# MCSPI_MCSPI_20100000h register map
Vendor: Texas Instruments
Peripheral module from a debugger description file (folder AM275x).
Registers are 32-bit, read-only, reset values left out (the file's numbers can be read two ways) unless marked. A register's access mark holds for its fields unless they carry their own. Offsets are as the file gives them; lines under a group give offsets from that group; [hi:lo] are bit positions; {n}, {i} and the like mark numbered series; 'fields as' and 'values as' point back to an identical list; <NAME> marks a mode.

## mcspi
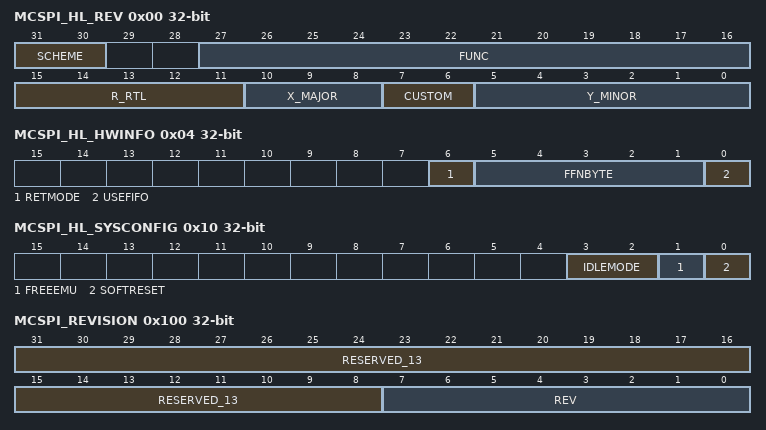
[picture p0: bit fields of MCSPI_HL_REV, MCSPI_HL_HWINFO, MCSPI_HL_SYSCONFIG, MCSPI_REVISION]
0x00 MCSPI_HL_REV — IP Revision Identifier (X.Y.R)Used by software to track features, bugs, and compatibility
  [31:30] SCHEME — Used to distinguish between old scheme and current
  [27:16] FUNC — Function indicates a software compatible module family If there is no level of software compatibility a new Func number [and hence REVISION] should be assigned
  [15:11] R_RTL — RTL Version [R], maintained by IP design owner RTL follows a numbering such as XYRZ which are explained in this table R changes ONLY when: [1] PDS uploads occur which may have been due to spec changes [2] Bug fixes occur [3] Resets to '0' when X or Y changes Design team has an internal 'Z' [customer invisible] number which increments on every drop that happens due to DV and RTL updates Z resets to 0 when R increments
  [10:8] X_MAJOR — Major Revision [X], maintained by IP specification owner X changes ONLY when: [1] There is a major feature addition An example would be adding Controller Mode to Utopia Level2 The Func field [or Class/Type in old PID format] will remain the same X does NOT change due to: [1] Bug fixes [2] Change in feature parameters
  [7:6] CUSTOM — Indicates a special version for a particular device Consequence of use may avoid use of standard Chip Support Library [CSL] / Drivers
  [5:0] Y_MINOR — Minor Revision [Y], maintained by IP specification owner Y changes ONLY when: [1] Features are scaled [up or down] Flexibility exists in that this feature scalability may either be represented in the Y change or a specific register in the IP that indicates which features are exactly available [2] When feature creeps from Is-Not list to Is list But this may not be the case once it sees silicon; in which case X will change Y does NOT change due to: [1] Bug fixes [2] Typos or clarifications [3] major functional/feature change/addition/deletion Instead these changes may be reflected via R, S, X as applicable Spec owner maintains a customer-invisible number 'S' which changes due to: [1] Typos/clarifications [2] Bug documentation Note that this bug is not due to a spec change but due to implementation Nevertheless, the spec tracks the IP bugs An RTL release [say for silicon PG11] that occurs due to bug fix should document the corresponding spec number [XYS] in its release notes
0x04 MCSPI_HL_HWINFO — Information about the IP module's hardware configuration, i.e. typically the module's HDL generics (if any).Actual field format and encoding is up to the module's designer to decide.
  [6] RETMODE — This bit field indicates whether the retention mode is supported using the pin PIRFFRET 0 Retention mode disabled1 Retention mode enabled
  [5:1] FFNBYTE — FIFO number of byte generic parameter This register defines the value of FFNBYTE generic parameter, only MSB bits from 8 down to 4 are taken into account 1 FIFO 16 bytes depth2 FIFO 32 bytes depth4 FIFO 64 bytes depth8 FIFO 128 bytes depth10 FIFO 256 bytes depth
  [0] USEFIFO — Use of a FIFO enable: This bit field indicates if a FIFO is integrated within controller design with its management 0 FIFO not implemented in design1 FIFO and its management implemented in design with depth defined by FFNBYTE generic
0x10 MCSPI_HL_SYSCONFIG rw — Clock management configuration
  [3:2] IDLEMODE — Configuration of the local target state management mode By definition, target can handle read/write transaction as long as it is out of IDLE state 0 Force-idle mode: local target's IDLE state follows (acknowledges) the system's clock stop requests unconditionally, that is, regardless of the IP module's internal requirements. Backup mode, for debug only.1 No-idle mode: local target never enters IDLE state. Backup mode, for debug only.2 Smart-idle mode: local target's IDLE state eventually follows (acknowledges) the system's clock stop requests, depending on the IP module's internal requirements. IP module shall not generate (IRQ- or DMA- request-related) wake-up events.3 Smart-idle wake-up-capable mode: local target's IDLE state eventually follows (acknowledges) the system's clock stop requests, depending on the IP module's internal requirements. IP module may generate (IRQ- or DMA-request-related) wake-up events when in IDLE state.
  [1] FREEEMU — Sensitivity to emulation [debug] suspend input signal 0 IP module is sensitive to emulation suspend.1 IP module is not sensitive to emulation suspend.
  [0] SOFTRESET — Software reset [Optional] 0 Reset done, no pending action1 Initiate software reset
0x100 MCSPI_REVISION — This register contains the hard coded RTL revision number.
  [31:8] RESERVED_13 — Reads returns 0
  [7:0] REV — IP revision [7:4] Major revision [3:0] Minor revision Examples: 0x10 for 10, 0x21 for 21
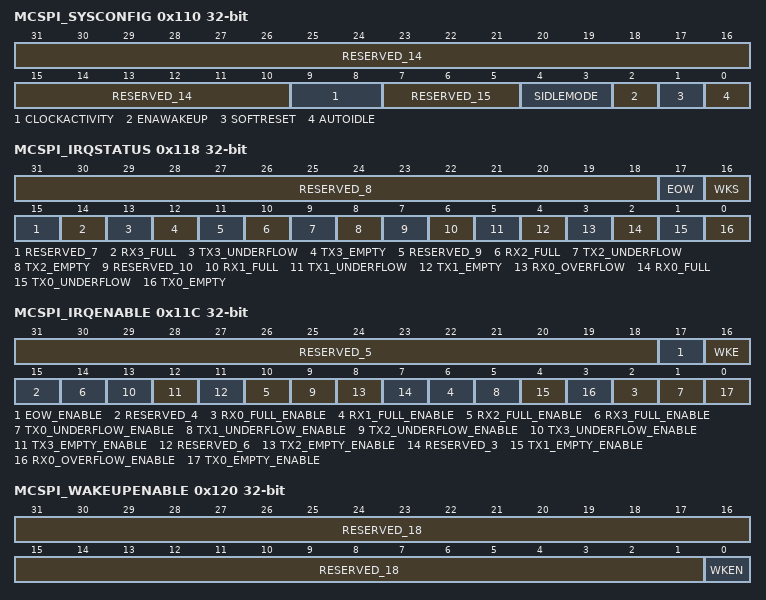
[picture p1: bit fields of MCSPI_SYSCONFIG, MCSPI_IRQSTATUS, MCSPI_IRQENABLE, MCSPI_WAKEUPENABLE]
0x110 MCSPI_SYSCONFIG access per field — This register allows controlling various parameters of the OCP interface.
  [31:10] RESERVED_14 ro — Reads returns 0
  [9:8] CLOCKACTIVITY rw — Clocks activity during wake up mode period 0 Interface and functional clocks may be switched off.1 Interface clock is maintained. Functional clock may be switched off.2 Functional clock is maintained. Interface clock may be switched off.3 Interface and functional clocks are maintained.
  [7:5] RESERVED_15 ro — Reads returns 0
  [4:3] SIDLEMODE rw — Power management 0 If an IDLE request is detected, the MCSPI acknowledges it unconditionally and goes in inactive mode. Interrupt, DMA requests and wake-up lines are unconditionally deasserted and the module wake-up capability is deactivated even if the MCSPI_SYSCONFIG[2] ENAWAKEUP bit is set.1 If an IDLE request is detected, the request is ignored and the module does not switch to wake-up mode, and keeps on behaving normally.2 If an IDLE request is detected, the module will switch to wake-up mode based on its internal activity, and the wake-up capability can be used if the bit MCSPI_SYSCONFIG[2] ENAWAKEUP is set.3 Reserved - do not use.
  [2] ENAWAKEUP rw — WakeUp feature control 0 Wake-up capability is disabled.1 Wake-up capability is enabled.
  [1] SOFTRESET rw — Software reset During reads it always returns 0 0 (write) Normal mode1 (write) Set this bit to 1 to trigger a module reset. The bit is automatically reset by the hardware.
  [0] AUTOIDLE rw — Internal OCP Clock gating strategy 0 Interface clock is free-running.1 Automatic interface clock gating strategy is applied, based on the configuration interface activity.
0x114 MCSPI_SYSSTATUS — This register provides status information about the module excluding the interrupt status information
  [0] RESETDONE — Internal Reset Monitoring 0 Internal module reset is ongoing1 Reset completed
0x118 MCSPI_IRQSTATUS access not given — The interrupt status regroups all the status of the module internal events that can generate an interrupt
  [31:18] RESERVED_8 ro — Reads returns 0
  [17] EOW — End of word count event when a channel is enabled using the FIFO buffer and the channel had sent the number of SPI word defined by MCSPI_XFERLEVEL[WCNT] 0 Event false1 Event status bit is reset (access R/W1TS)
  [16] WKS — Wake Up event in target mode when an active control signal is detected on the SPIEN line programmed in the field MCSPI_CH0CONF[SPIENSLV] 0 Event status bit unchanged1 Event is pending (access R/W1TS)
  [15] RESERVED_7 ro — Reads returns 0
  [14] RX3_FULL — Receiver register is full or almost full Only when Channel 3 is enabled 0 Event status bit unchanged1 Event is pending (access R/W1TS)
  [13] TX3_UNDERFLOW — Transmitter register underflow Only when Channel 3 is enabled The transmitter register is empty [not updated by Host or DMA with new data] before its time slot assignment Exception: No TX_underflow event when no data has been loaded into the transmitter register since channel has been enabled 0 Event status bit unchanged1 Event is pending (access R/W1TS)
  [12] TX3_EMPTY — Transmitter register is empty or almost empty Note: Enabling the channel automatically rises this event 0 Event status bit unchanged1 Event is pending (access R/W1TS)
  [11] RESERVED_9 ro — Reads returns 0
  [10] RX2_FULL — Receiver register full or almost full Channel 2 0 Event status bit unchanged1 Event is pending (access R/W1TS)
  [9] TX2_UNDERFLOW — Transmitter register underflow Channel 2 0 Event status bit unchanged1 Event is pending (access R/W1TS)
  [8] TX2_EMPTY — Transmitter register empty or almost empty Channel 2 0 Event status bit unchanged1 Event is pending (access R/W1TS)
  [7] RESERVED_10 ro — Reads returns 0
  [6] RX1_FULL — Receiver register full or almost full Channel 1 0 Event status bit unchanged1 Event is pending (access R/W1TS)
  [5] TX1_UNDERFLOW — Transmitter register underflow Channel 1 0 Event status bit unchanged1 Event is pending (access R/W1TS)
  [4] TX1_EMPTY — Transmitter register empty or almost empty Channel 1 0 Event status bit unchanged1 Event is pending (access R/W1TS)
  [3] RX0_OVERFLOW — Receiver register overflow [target mode only] Channel 0 0 Event status bit unchanged1 Event is pending (access R/W1TS)
  [2] RX0_FULL — Receiver register full or almost full Channel 0 0 Event status bit unchanged1 Event is pending (access R/W1TS)
  [1] TX0_UNDERFLOW — Transmitter register underflow Channel 0 0 Event status bit unchanged1 Event is pending (access R/W1TS)
  [0] TX0_EMPTY — Transmitter register empty or almost empty Channel 0 0 Event status bit unchanged1 Event is pending (access R/W1TS)
0x11C MCSPI_IRQENABLE access per field — This register allows to enable/disable the module internal sources of interrupt, on an event-by-event basis.
  [31:18] RESERVED_5 ro — Reads return 0
  [17] EOW_ENABLE rw — End of Word count Interrupt Enable 0 Interrupt disabled1 Interrupt enabled
  [16] WKE rw — Wake Up event interrupt Enable in target mode when an active control signal is detected on the SPIEN line programmed in the field MCSPI_CH0CONF[SPIENSLV] 0 Interrupt disabled1 Interrupt enabled
  [15] RESERVED_4 ro — Reads returns 0
  [4n+2] RX{n}_FULL_ENABLE rw (n=0..3) — Receiver register Full Interrupt Enable Ch {n} 0 Interrupt disabled1 Interrupt enabled
  [4n+1] TX{n}_UNDERFLOW_ENABLE rw (n=0..3) — Transmitter register Underflow Interrupt Enable Ch {n} 0 Interrupt disabled1 Interrupt enabled
  [12] TX3_EMPTY_ENABLE rw — Transmitter register Empty Interrupt Enable Ch3 0 Interrupt disabled1 Interrupt enabled
  [11] RESERVED_6 ro — Reads return 0
  [8] TX2_EMPTY_ENABLE rw — Transmitter register Empty Interrupt Enable Ch 2 0 Interrupt disabled1 Interrupt enabled
  [7] RESERVED_3 ro — Reads return 0
  [4] TX1_EMPTY_ENABLE rw — Transmitter register Empty Interrupt Enable Ch 1 0 Interrupt disabled1 Interrupt enabled
  [3] RX0_OVERFLOW_ENABLE rw — Receiver register Overflow Interrupt Enable Ch 0 0 Interrupt disabled1 Interrupt enabled
  [0] TX0_EMPTY_ENABLE rw — Transmitter register Empty Interrupt Enable Ch 0 0 Interrupt disabled1 Interrupt enabled
0x120 MCSPI_WAKEUPENABLE access per field — The wakeup enable register allows to enable/disable the module internal sources of wakeup on event-by-event basis.
  [31:1] RESERVED_18 ro — Reads returns 0
  [0] WKEN rw — WakeUp functionality in target mode when an active control signal is detected on the SPIEN line programmed in the field MCSPI_CH0CONF[SPIENSLV] 0 The event is not allowed to wake-up the system, even if the global control bit MCSPI_SYSCONFIG[2] ENAWAKEUPis set.1 The event is allowed to wake-up the system if the global control bit MCSPI_SYSCONFIG[2] ENAWAKEUP is set.
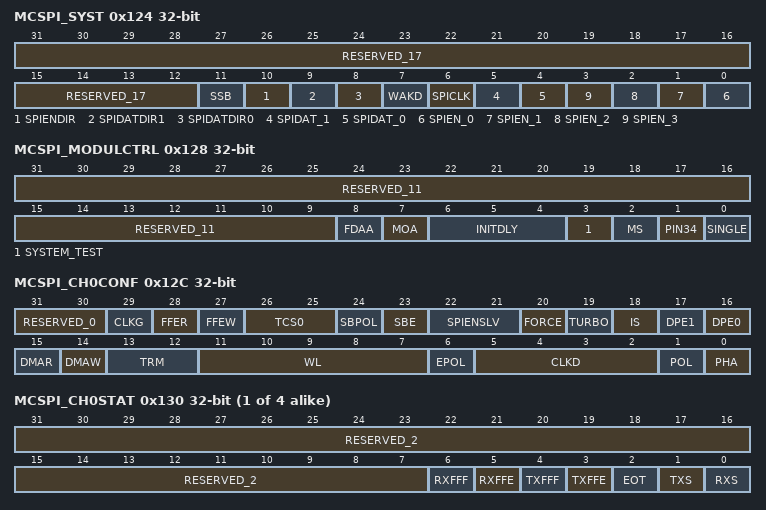
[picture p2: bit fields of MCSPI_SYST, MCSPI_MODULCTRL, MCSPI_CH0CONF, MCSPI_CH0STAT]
0x124 MCSPI_SYST access per field — This register is used to check the correctness of the system interconnect either internally to peripheral bus, or externally to device IO pads, when the module is configured in system test (SYSTEST) mode.
  [31:12] RESERVED_17 ro — Reads returns 0
  [11] SSB rw — Set status bit 0 No action. Writing 0 does not clear already set status bits. This bit must be cleared before trying to clear a status bit of the MCSPI_IRQSTATUS register.1 Force to 1 all status bits of MCSPI_IRQSTATUS register. Writing 1 into this bit sets to 1 all status bits in the MCSPI_IRQSTATUS register.
  [10] SPIENDIR rw — Set the direction of the SPIEN[3:0] lines and SPICLK line 0 Output (as in controller mode)1 Input (as in peripheral mode)
  [9] SPIDATDIR1 rw — Set the direction of the SPIDAT[1] 0 Output1 Input
  [8] SPIDATDIR0 rw — Set the direction of the SPIDAT[0] 0 Output1 Input
  [7] WAKD rw — SWAKEUP output [signal data value of internal signal to system] The signal is driven high or low according to the value written into this register bit 0 The pin is driven low.1 The pin is driven high.
  [6] SPICLK rw — SPICLK line [signal data value] If MCSPI_SYST[SPIENDIR] = 1 [input mode direction], this bit returns the value on the CLKSPI line [high or low], and a write into this bit has no effect If MCSPI_SYST[SPIENDIR] = 0 [output mode direction], the CLKSPI line is driven high or low according to the value written into this register
  [5] SPIDAT_1 rw — SPIDAT[1] line [signal data value] If MCSPI_SYST[SPIDATDIR1] = 0 [output mode direction], the SPIDAT[1] line is driven high or low according to the value written into this register If MCSPI_SYST[SPIDATDIR1] = 1 [input mode direction], this bit returns the value on the SPIDAT[1] line [high or low], and a write into this bit has no effect
  [4] SPIDAT_0 rw — SPIDAT[0] line [signal data value] If MCSPI_SYST[SPIDATDIR0] = 0 [output mode direction], the SPIDAT[0] line is driven high or low according to the value written into this register If MCSPI_SYST[SPIDATDIR0] = 1 [input mode direction], this bit returns the value on the SPIDAT[0] line [high or low], and a write into this bit has no effect
  [n] SPIEN_{n} rw (n=0..3) — SPIEN[{n}] line [signal data value] If MCSPI_SYST[SPIENDIR] = 0 [output mode direction], the SPIENT[{n}] line is driven high or low according to the value written into this register If MCSPI_SYST[SPIENDIR] = 1 [input mode direction], this bit returns the value on the SPIEN[{n}] line [high or low], and a write into this bit has no effect
0x128 MCSPI_MODULCTRL access per field — This register is dedicated to the configuration of the serial port interface.
  [31:9] RESERVED_11 ro — Reads returns 0
  [8] FDAA rw — FIFO DMA Address 256-bit aligned This register is used when a FIFO is managed by the module and DMA connected to the controller provides only 256 bit aligned address If this bit is set the enabled channel which uses the FIFO has its datas managed through MCSPI_DAFTX and MCSPI_DAFRX registers instead of MCSPI_TX[i] and MCSPI_RX[i] registers 0 FIFO data managed by MCSPI_TX(i) and MCSPI_RX(i) registers.1 FIFO data managed by MCSPI_DAFTX and MCSPI_DAFRX registers.
  [7] MOA rw — Multiple word ocp access: This register can only be used when a channel is enabled using a FIFO It allows the system to perform multiple SPI word access for a single 32-bit OCP word access This is possible for WL < 16 0 Multiple word access disabled1 Multiple word access enabled with FIFO
  [6:4] INITDLY rw — Initial spi delay for first transfer: This register is an option only available in SINGLE controller mode, The controller waits for a delay to transmit the first spi word after channel enabled and corresponding TX register filled This Delay is based on SPI output frequency clock, No clock output provided to the boundary and chip select is not active in 4 pin mode within this period 0 No delay for first MCSPI transfer.1 The controller wait 4 MCSPI bus clock2 The controller wait 8 MCSPI bus clock3 The controller wait 16 MCSPI bus clock4 The controller wait 32 MCSPI bus clock
  [3] SYSTEM_TEST rw — Enables the system test mode 0 Functional mode1 System test mode (SYSTEST)
  [2] MS rw — Controller/ Target 0 Controller - The module generates the SPICLK and SPIEN[3:0].1 Peripheral - The module receives the SPICLK and SPIEN[3:0].
  [1] PIN34 rw — Pin mode selection: This register is used to configure the SPI pin mode, in controller or target mode If asserted the controller only use SIMO,SOMI and SPICLK clock pin for spi transfers 0 SPIEN is used as a chip-select.1 SPIEN is not used. In this mode all related options to chip-select have no meaning.
  [0] SINGLE rw — Single channel / Multi Channel [controller mode only] 0 More than one channel will be used in controller mode.1 Only one channel will be used in controller mode. This bit must be set in Force SPIEN[i] mode.
0x12C MCSPI_CH0CONF access per field — This register is dedicated to the configuration of the channel 0
  [31:30] RESERVED_0 ro — read returns 0
  [29] CLKG rw — Clock divider granularity This register defines the granularity of channel clock divider: power of two or one clock cycle granularity When this bit is set the register MCSPI_CHCTRL[EXTCLK] must be configured to reach a maximum of 4096 clock divider ratio Then The clock divider ratio is a concatenation of MCSPI_CHCONF[CLKD] and MCSPI_CHCTRL[EXTCLK] values 0 Clock granularity of power of 21 One clock cycle granularity
  [28] FFER rw — FIFO enabled for receive:Only one channel can have this bit field set 0 The buffer is not used to receive data.1 The buffer is used to receive data.
  [27] FFEW rw — FIFO enabled for Transmit:Only one channel can have this bit field set 0 The buffer is not used to transmit data.1 The buffer is used to transmit data.
  [26:25] TCS0 rw — Chip Select Time Control This 2-bits field defines the number of interface clock cycles between CS toggling and first or last edge of SPI clock 0 0.5 clock cycle1 1.5 clock cycles2 2.5 clock cycles3 3.5 clock cycles
  [24] SBPOL rw — Start bit polarity 0 SPICLK is held low during the INACTIVE state1 SPICLK is held high during the INACTIVE state
  [23] SBE rw — Start bit enable for SPI transfer 0 Default MCSPI transfer length as specified by WL bit field1 Start bit D/CX added before MCSPI transfer polarity is defined by MCSPI_CHCONF_0[24] SBPOL
  [22:21] SPIENSLV rw — Channel 0 only and target mode only: SPI target select signal detection Reserved bits for other cases 0 Detection enabled only on SPIEN[0]1 Detection enabled only on SPIEN[1]2 Detection enabled only on SPIEN[2]3 Detection enabled only on SPIEN[3]
  [20] FORCE rw — Manual SPIEN assertion to keep SPIEN active between SPI words [single channel controller mode only] 0 Writing 0 into this bit drives low the SPIEN line when MCSPI_CHCONF_0/1/2/3[6] EPOL=0, and drives it high when MCSPI_CHCONF_0/1/2/3[6] EPOL=1.1 Writing 1 into this bit drives high the SPIEN line when MCSPI_CHCONF_0/1/2/3[6] EPOL=0, and drives it low when MCSPI_CHCONF_0/1/2/3[6] EPOL=1.
  [19] TURBO rw — Turbo mode 0 Turbo is deactivated (recommended for single MCSPI word transfer).1 Turbo is activated to maximize the throughput for multiple MCSPI words transfer.
  [18] IS rw — Input Select 0 Data line 0 (SPIDAT[0]) selected for reception1 Data line 1 (SPIDAT[1]) selected for reception
  [17] DPE1 rw — Transmission Enable for data line 1 [SPIDATAGZEN[1]] 0 Data line 1 (SPIDAT[1]) selected for transmission1 No transmission on Data Line1 (SPIDAT[1])
  [16] DPE0 rw — Transmission Enable for data line 0 [SPIDATAGZEN[0]] 0 Data Line0 (SPIDAT[0]) selected for transmission1 No transmission on data line 0 (SPIDAT[0])
  [15] DMAR rw — DMA Read request The DMA Read request line is asserted when the channel is enabled and a new data is available in the receive register of the channel The DMA Read request line is deasserted on read completion of the receive register of the channel 0 DMA read request disabled1 DMA read request enabled
  [14] DMAW rw — DMA Write request The DMA Write request line is asserted when The channel is enabled and the transmitter register of the channel is empty The DMA Write request line is deasserted on load completion of the transmitter register of the channel 0 DMA write request disabled1 DMA write request enabled
  [13:12] TRM rw — Transmit/Receive modes 0 Transmit-and-receive mode1 Receive-only mode2 Transmit-only mode3 Reserved
  [11:7] WL rw — SPI word length 0 Reserved1 Reserved2 Reserved3 The MCSPI word is 4 bits long4 The MCSPI word is 5 bits long5 The MCSPI word is 6 bits long6 The MCSPI word is 7 bits long7 The MCSPI word is 8 bits long8 The MCSPI word is 9 bits long9 The MCSPI word is 10 bits longA The MCSPI word is 11 bits longB The MCSPI word is 12 bits longC The MCSPI word is 13 bits longD The MCSPI word is 14 bits longE The MCSPI word is 15 bits longF The MCSPI word is 16 bits long10 The MCSPI word is 17 bits long11 The MCSPI word is 18 bits long12 The MCSPI word is 19 bits long13 The MCSPI word is 20 bits long14 The MCSPI word is 21 bits long15 The MCSPI word is 22 bits long16 The MCSPI word is 23 bits long17 The MCSPI word is 24 bits long18 The MCSPI word is 25 bits long19 The MCSPI word is 26 bits long1A The MCSPI word is 27 bits long1B The MCSPI word is 28 bits long1C The MCSPI word is 29 bits long1D The MCSPI word is 30 bits long1E The MCSPI word is 31 bits long1F The MCSPI word is 32 bits long
  [6] EPOL rw — SPIEN polarity 0 SPICLK is held low during the INACTIVE state1 SPICLK is held high during the INACTIVE state
  [5:2] CLKD rw — Frequency divider for SPICLK [only when the module is a Controller SPI device] A programmable clock divider divides the SPI reference clock [CLKSPIREF] with a 4-bit value, and results in a new clock SPICLK available to shift-in and shift-out data By default the clock divider ratio has a power of two granularity when MCSPI_CHCONF[CLKG] is cleared, Otherwise this register is the 4 LSB bit of a 12-bit register concatenated with clock divider extension MCSPI_CHCTRL[EXTCLK] registerThe value description below defines the clock ratio when MCSPI_CHCONF[CLKG] is set to 0 0 11 22 43 84 165 326 647 1288 2569 512A 1024B 2048C 4096D 8192E 16384F 32768
  [1] POL rw — SPICLK polarity 0 SPICLK is held low during the INACTIVE state1 SPICLK is held high during the INACTIVE state
  [0] PHA rw — SPICLK phase 0 Data are latched on odd-numbered edges of SPICLK.1 Data are latched on even-numbered edges of SPICLK.
{0x130+0x14*i} MCSPI_CH{i}STAT (i=0..3) — This register provides status information about transmitter and receiver registers of channel {i}
  [31:7] RESERVED_2 — Read returns 0
  [6] RXFFF — Channel 'i' FIFO Receive Buffer Full Status 0 FIFO receive buffer is not full1 FIFO receive buffer is full
  [5] RXFFE — Channel 'i' FIFO Receive Buffer Empty Status 0 FIFO receive buffer is not empty1 FIFO receive buffer is empty
  [4] TXFFF — Channel 'i' FIFO Transmit Buffer Full Status 0 FIFO transmit buffer is not full1 FIFO transmit buffer is full
  [3] TXFFE — Channel 'i' FIFO Transmit Buffer Empty Status 0 FIFO transmit buffer is not empty1 FIFO transmit buffer is empty
  [2] EOT — Channel 'i' End of transfer Status The definitions of beginning and end of transfer vary with controller versus target and the transfer format [Transmit/Receive modes, Turbo mode] See dedicated chapters for details 0 This flag is automatically cleared when the shift register is loaded with the data from the transmitter register (beginning of transfer).1 This flag is automatically set to one at the end of an MCSPI transfer.
  [1] TXS — Channel 'i' Transmitter Register Status 0 Register is full.1 Register is empty.
  [0] RXS — Channel 'i' Receiver Register Status 0 Register is empty.1 Register is full.
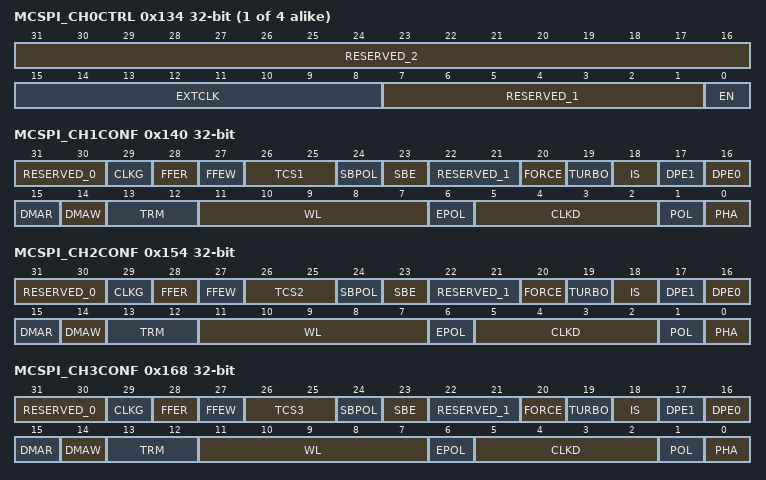
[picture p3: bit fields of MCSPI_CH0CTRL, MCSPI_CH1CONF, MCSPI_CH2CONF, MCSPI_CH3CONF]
{0x134+0x14*i} MCSPI_CH{i}CTRL access per field (i=0..3) — This register is dedicated to enable the channel {i}
  [31:16] RESERVED_2 ro — Read returns 0
  [15:8] EXTCLK rw — Clock ratio extension: This register is used to concatenate with MCSPI_CHCONF[CLKD] register for clock ratio only when granularity is one clock cycle [MCSPI_CHCONF[CLKG] set to 1] Then the max value reached is 4096 clock divider ratio 0 Clock ratio is CLKD + 1.1 Clock ratio is CLKD + 1 + 16.FF Clock ratio is CLKD + 1 + 4080.
  [7:1] RESERVED_1 ro — Read returns 0
  [0] EN rw — Channel Enable 0 Channel i is not active.1 Channel i is active.
{0x138+0x14*i} MCSPI_TX{i} rw (i=0..3) — This register contains a single SPI word to transmit on the serial link, what ever SPI word length is.
  [31:0] TDATA — Channel {i} Data to transmit
{0x13C+0x14*i} MCSPI_RX{i} (i=0..3) — This register contains a single SPI word received through the serial link, what ever SPI word length is.
  [31:0] RDATA — Channel {i} Received Data
0x140 MCSPI_CH1CONF access per field — This register is dedicated to the configuration of the channel.
  [31:30] RESERVED_0 ro — read returns 0
  [29] CLKG rw — Clock divider granularity This register defines the granularity of channel clock divider: power of two or one clock cycle granularity When this bit is set the register MCSPI_CHCTRL[EXTCLK] must be configured to reach a maximum of 4096 clock divider ratio Then The clock divider ratio is a concatenation of MCSPI_CHCONF[CLKD] and MCSPI_CHCTRL[EXTCLK] values 0 Clock granularity of power of 21 One clock cycle granularity
  [28] FFER rw — FIFO enabled for receive:Only one channel can have this bit field set 0 The buffer is not used to receive data.1 The buffer is used to receive data.
  [27] FFEW rw — FIFO enabled for Transmit:Only one channel can have this bit field set 0 The buffer is not used to transmit data.1 The buffer is used to transmit data.
  [26:25] TCS1 rw — Chip Select Time Control This 2-bits field defines the number of interface clock cycles between CS toggling and first or last edge of SPI clock 0 0.5 clock cycle1 1.5 clock cycles2 2.5 clock cycles3 3.5 clock cycles
  [24] SBPOL rw — Start bit polarity 0 SPICLK is held low during the INACTIVE state1 SPICLK is held high during the INACTIVE state
  [23] SBE rw — Start bit enable for SPI transfer 0 Default MCSPI transfer length as specified by WL bit field1 Start bit D/CX added before MCSPI transfer polarity is defined by MCSPI_CHCONF_0[24] SBPOL
  [22:21] RESERVED_1 ro — read returns 0
  [20] FORCE rw — Manual SPIEN assertion to keep SPIEN active between SPI words [single channel controller mode only] 0 Writing 0 into this bit drives low the SPIEN line when MCSPI_CHCONF_0/1/2/3[6] EPOL=0, and drives it high when MCSPI_CHCONF_0/1/2/3[6] EPOL=1.1 Writing 1 into this bit drives high the SPIEN line when MCSPI_CHCONF_0/1/2/3[6] EPOL=0, and drives it low when MCSPI_CHCONF_0/1/2/3[6] EPOL=1.
  [19] TURBO rw — Turbo mode 0 Turbo is deactivated (recommended for single MCSPI word transfer).1 Turbo is activated to maximize the throughput for multiple MCSPI words transfer.
  [18] IS rw — Input Select 0 Data line 0 (SPIDAT[0]) selected for reception1 Data line 1 (SPIDAT[1]) selected for reception
  [17] DPE1 rw — Transmission Enable for data line 1 [SPIDATAGZEN[1]] 0 Data line 1 (SPIDAT[1]) selected for transmission1 No transmission on Data Line1 (SPIDAT[1])
  [16] DPE0 rw — Transmission Enable for data line 0 [SPIDATAGZEN[0]] 0 Data Line0 (SPIDAT[0]) selected for transmission1 No transmission on data line 0 (SPIDAT[0])
  [15] DMAR rw — DMA Read request The DMA Read request line is asserted when the channel is enabled and a new data is available in the receive register of the channel The DMA Read request line is deasserted on read completion of the receive register of the channel 0 DMA read request disabled1 DMA read request enabled
  [14] DMAW rw — DMA Write request The DMA Write request line is asserted when The channel is enabled and the transmitter register of the channel is empty The DMA Write request line is deasserted on load completion of the transmitter register of the channel 0 DMA write request disabled1 DMA write request enabled
  [13:12] TRM rw — Transmit/Receive modes 0 Transmit-and-receive mode1 Receive-only mode2 Transmit-only mode3 Reserved
  [11:7] WL rw — SPI word length 0 Reserved1 Reserved2 Reserved3 The MCSPI word is 4 bits long4 The MCSPI word is 5 bits long5 The MCSPI word is 6 bits long6 The MCSPI word is 7 bits long7 The MCSPI word is 8 bits long8 The MCSPI word is 9 bits long9 The MCSPI word is 10 bits longA The MCSPI word is 11 bits longB The MCSPI word is 12 bits longC The MCSPI word is 13 bits longD The MCSPI word is 14 bits longE The MCSPI word is 15 bits longF The MCSPI word is 16 bits long10 The MCSPI word is 17 bits long11 The MCSPI word is 18 bits long12 The MCSPI word is 19 bits long13 The MCSPI word is 20 bits long14 The MCSPI word is 21 bits long15 The MCSPI word is 22 bits long16 The MCSPI word is 23 bits long17 The MCSPI word is 24 bits long18 The MCSPI word is 25 bits long19 The MCSPI word is 26 bits long1A The MCSPI word is 27 bits long1B The MCSPI word is 28 bits long1C The MCSPI word is 29 bits long1D The MCSPI word is 30 bits long1E The MCSPI word is 31 bits long1F The MCSPI word is 32 bits long
  [6] EPOL rw — SPIEN polarity 0 SPICLK is held low during the INACTIVE state1 SPICLK is held high during the INACTIVE state
  [5:2] CLKD rw — Frequency divider for SPICLK [only when the module is a Controller SPI device] A programmable clock divider divides the SPI reference clock [CLKSPIREF] with a 4-bit value, and results in a new clock SPICLK available to shift-in and shift-out data By default the clock divider ratio has a power of two granularity when MCSPI_CHCONF[CLKG] is cleared, Otherwise this register is the 4 LSB bit of a 12-bit register concatenated with clock divider extension MCSPI_CHCTRL[EXTCLK] registerThe value description below defines the clock ratio when MCSPI_CHCONF[CLKG] is set to 0 0 11 22 43 84 165 326 647 1288 2569 512A 1024B 2048C 4096D 8192E 16384F 32768
  [1] POL rw — SPICLK polarity 0 SPICLK is held low during the INACTIVE state1 SPICLK is held high during the INACTIVE state
  [0] PHA rw — SPICLK phase 0 Data are latched on odd-numbered edges of SPICLK.1 Data are latched on even-numbered edges of SPICLK.
0x154 MCSPI_CH2CONF access per field — This register is dedicated to the configuration of the channel 2
  [31:30] RESERVED_0 ro — read returns 0
  [29] CLKG rw — Clock divider granularity This register defines the granularity of channel clock divider: power of two or one clock cycle granularity When this bit is set the register MCSPI_CHCTRL[EXTCLK] must be configured to reach a maximum of 4096 clock divider ratio Then The clock divider ratio is a concatenation of MCSPI_CHCONF[CLKD] and MCSPI_CHCTRL[EXTCLK] values 0 Clock granularity of power of 21 One clock cycle granularity
  [28] FFER rw — FIFO enabled for receive:Only one channel can have this bit field set 0 The buffer is not used to receive data.1 The buffer is used to receive data.
  [27] FFEW rw — FIFO enabled for Transmit:Only one channel can have this bit field set 0 The buffer is not used to transmit data.1 The buffer is used to transmit data.
  [26:25] TCS2 rw — Chip Select Time Control This 2-bits field defines the number of interface clock cycles between CS toggling and first or last edge of SPI clock 0 0.5 clock cycle1 1.5 clock cycles2 2.5 clock cycles3 3.5 clock cycles
  [24] SBPOL rw — Start bit polarity 0 SPICLK is held low during the INACTIVE state1 SPICLK is held high during the INACTIVE state
  [23] SBE rw — Start bit enable for SPI transfer 0 Default MCSPI transfer length as specified by WL bit field1 Start bit D/CX added before MCSPI transfer polarity is defined by MCSPI_CHCONF_0[24] SBPOL
  [22:21] RESERVED_1 ro — read returns 0
  [20] FORCE rw — Manual SPIEN assertion to keep SPIEN active between SPI words [single channel controller mode only] 0 Writing 0 into this bit drives low the SPIEN line when MCSPI_CHCONF_0/1/2/3[6] EPOL=0, and drives it high when MCSPI_CHCONF_0/1/2/3[6] EPOL=1.1 Writing 1 into this bit drives high the SPIEN line when MCSPI_CHCONF_0/1/2/3[6] EPOL=0, and drives it low when MCSPI_CHCONF_0/1/2/3[6] EPOL=1.
  [19] TURBO rw — Turbo mode 0 Turbo is deactivated (recommended for single MCSPI word transfer).1 Turbo is activated to maximize the throughput for multiple MCSPI words transfer.
  [18] IS rw — Input Select 0 Data line 0 (SPIDAT[0]) selected for reception1 Data line 1 (SPIDAT[1]) selected for reception
  [17] DPE1 rw — Transmission Enable for data line 1 [SPIDATAGZEN[1]] 0 Data line 1 (SPIDAT[1]) selected for transmission1 No transmission on Data Line1 (SPIDAT[1])
  [16] DPE0 rw — Transmission Enable for data line 0 [SPIDATAGZEN[0]] 0 Data Line0 (SPIDAT[0]) selected for transmission1 No transmission on data line 0 (SPIDAT[0])
  [15] DMAR rw — DMA Read request The DMA Read request line is asserted when the channel is enabled and a new data is available in the receive register of the channel The DMA Read request line is deasserted on read completion of the receive register of the channel 0 DMA read request disabled1 DMA read request enabled
  [14] DMAW rw — DMA Write request The DMA Write request line is asserted when The channel is enabled and the transmitter register of the channel is empty The DMA Write request line is deasserted on load completion of the transmitter register of the channel 0 DMA write request disabled1 DMA write request enabled
  [13:12] TRM rw — Transmit/Receive modes 0 Transmit-and-receive mode1 Receive-only mode2 Transmit-only mode3 Reserved
  [11:7] WL rw — SPI word length 0 Reserved1 Reserved2 Reserved3 The MCSPI word is 4 bits long4 The MCSPI word is 5 bits long5 The MCSPI word is 6 bits long6 The MCSPI word is 7 bits long7 The MCSPI word is 8 bits long8 The MCSPI word is 9 bits long9 The MCSPI word is 10 bits longA The MCSPI word is 11 bits longB The MCSPI word is 12 bits longC The MCSPI word is 13 bits longD The MCSPI word is 14 bits longE The MCSPI word is 15 bits longF The MCSPI word is 16 bits long10 The MCSPI word is 17 bits long11 The MCSPI word is 18 bits long12 The MCSPI word is 19 bits long13 The MCSPI word is 20 bits long14 The MCSPI word is 21 bits long15 The MCSPI word is 22 bits long16 The MCSPI word is 23 bits long17 The MCSPI word is 24 bits long18 The MCSPI word is 25 bits long19 The MCSPI word is 26 bits long1A The MCSPI word is 27 bits long1B The MCSPI word is 28 bits long1C The MCSPI word is 29 bits long1D The MCSPI word is 30 bits long1E The MCSPI word is 31 bits long1F The MCSPI word is 32 bits long
  [6] EPOL rw — SPIEN polarity 0 SPICLK is held low during the INACTIVE state1 SPICLK is held high during the INACTIVE state
  [5:2] CLKD rw — Frequency divider for SPICLK [only when the module is a Controller SPI device] A programmable clock divider divides the SPI reference clock [CLKSPIREF] with a 4-bit value, and results in a new clock SPICLK available to shift-in and shift-out data By default the clock divider ratio has a power of two granularity when MCSPI_CHCONF[CLKG] is cleared, Otherwise this register is the 4 LSB bit of a 12-bit register concatenated with clock divider extension MCSPI_CHCTRL[EXTCLK] registerThe value description below defines the clock ratio when MCSPI_CHCONF[CLKG] is set to 0 0 11 22 43 84 165 326 647 1288 2569 512A 1024B 2048C 4096D 8192E 16384F 32768
  [1] POL rw — SPICLK polarity 0 SPICLK is held low during the INACTIVE state1 SPICLK is held high during the INACTIVE state
  [0] PHA rw — SPICLK phase 0 Data are latched on odd-numbered edges of SPICLK.1 Data are latched on even-numbered edges of SPICLK.
0x168 MCSPI_CH3CONF access per field — This register is dedicated to the configuration of the channel 3
  [31:30] RESERVED_0 ro — read returns 0
  [29] CLKG rw — Clock divider granularity This register defines the granularity of channel clock divider: power of two or one clock cycle granularity When this bit is set the register MCSPI_CHCTRL[EXTCLK] must be configured to reach a maximum of 4096 clock divider ratio Then The clock divider ratio is a concatenation of MCSPI_CHCONF[CLKD] and MCSPI_CHCTRL[EXTCLK] values 0 Clock granularity of power of 21 One clock cycle granularity
  [28] FFER rw — FIFO enabled for receive:Only one channel can have this bit field set 0 The buffer is not used to receive data.1 The buffer is used to receive data.
  [27] FFEW rw — FIFO enabled for Transmit:Only one channel can have this bit field set 0 The buffer is not used to transmit data.1 The buffer is used to transmit data.
  [26:25] TCS3 rw — Chip Select Time Control This 2-bits field defines the number of interface clock cycles between CS toggling and first or last edge of SPI clock 0 0.5 clock cycle1 1.5 clock cycles2 2.5 clock cycles3 3.5 clock cycles
  [24] SBPOL rw — Start bit polarity 0 SPICLK is held low during the INACTIVE state1 SPICLK is held high during the INACTIVE state
  [23] SBE rw — Start bit enable for SPI transfer 0 Default MCSPI transfer length as specified by WL bit field1 Start bit D/CX added before MCSPI transfer polarity is defined by MCSPI_CHCONF_0[24] SBPOL
  [22:21] RESERVED_1 ro — read returns 0
  [20] FORCE rw — Manual SPIEN assertion to keep SPIEN active between SPI words [single channel controller mode only] 0 Writing 0 into this bit drives low the SPIEN line when MCSPI_CHCONF_0/1/2/3[6] EPOL=0, and drives it high when MCSPI_CHCONF_0/1/2/3[6] EPOL=1.1 Writing 1 into this bit drives high the SPIEN line when MCSPI_CHCONF_0/1/2/3[6] EPOL=0, and drives it low when MCSPI_CHCONF_0/1/2/3[6] EPOL=1.
  [19] TURBO rw — Turbo mode 0 Turbo is deactivated (recommended for single MCSPI word transfer).1 Turbo is activated to maximize the throughput for multiple MCSPI words transfer.
  [18] IS rw — Input Select 0 Data line 0 (SPIDAT[0]) selected for reception1 Data line 1 (SPIDAT[1]) selected for reception
  [17] DPE1 rw — Transmission Enable for data line 1 [SPIDATAGZEN[1]] 0 Data line 1 (SPIDAT[1]) selected for transmission1 No transmission on Data Line1 (SPIDAT[1])
  [16] DPE0 rw — Transmission Enable for data line 0 [SPIDATAGZEN[0]] 0 Data Line0 (SPIDAT[0]) selected for transmission1 No transmission on data line 0 (SPIDAT[0])
  [15] DMAR rw — DMA Read request The DMA Read request line is asserted when the channel is enabled and a new data is available in the receive register of the channel The DMA Read request line is deasserted on read completion of the receive register of the channel 0 DMA read request disabled1 DMA read request enabled
  [14] DMAW rw — DMA Write request The DMA Write request line is asserted when The channel is enabled and the transmitter register of the channel is empty The DMA Write request line is deasserted on load completion of the transmitter register of the channel 0 DMA write request disabled1 DMA write request enabled
  [13:12] TRM rw — Transmit/Receive modes 0 Transmit-and-receive mode1 Receive-only mode2 Transmit-only mode3 Reserved
  [11:7] WL rw — SPI word length 0 Reserved1 Reserved2 Reserved3 The MCSPI word is 4 bits long4 The MCSPI word is 5 bits long5 The MCSPI word is 6 bits long6 The MCSPI word is 7 bits long7 The MCSPI word is 8 bits long8 The MCSPI word is 9 bits long9 The MCSPI word is 10 bits longA The MCSPI word is 11 bits longB The MCSPI word is 12 bits longC The MCSPI word is 13 bits longD The MCSPI word is 14 bits longE The MCSPI word is 15 bits longF The MCSPI word is 16 bits long10 The MCSPI word is 17 bits long11 The MCSPI word is 18 bits long12 The MCSPI word is 19 bits long13 The MCSPI word is 20 bits long14 The MCSPI word is 21 bits long15 The MCSPI word is 22 bits long16 The MCSPI word is 23 bits long17 The MCSPI word is 24 bits long18 The MCSPI word is 25 bits long19 The MCSPI word is 26 bits long1A The MCSPI word is 27 bits long1B The MCSPI word is 28 bits long1C The MCSPI word is 29 bits long1D The MCSPI word is 30 bits long1E The MCSPI word is 31 bits long1F The MCSPI word is 32 bits long
  [6] EPOL rw — SPIEN polarity 0 SPICLK is held low during the INACTIVE state1 SPICLK is held high during the INACTIVE state
  [5:2] CLKD rw — Frequency divider for SPICLK [only when the module is a Controller SPI device] A programmable clock divider divides the SPI reference clock [CLKSPIREF] with a 4-bit value, and results in a new clock SPICLK available to shift-in and shift-out data By default the clock divider ratio has a power of two granularity when MCSPI_CHCONF[CLKG] is cleared, Otherwise this register is the 4 LSB bit of a 12-bit register concatenated with clock divider extension MCSPI_CHCTRL[EXTCLK] registerThe value description below defines the clock ratio when MCSPI_CHCONF[CLKG] is set to 0 0 11 22 43 84 165 326 647 1288 2569 512A 1024B 2048C 4096D 8192E 16384F 32768
  [1] POL rw — SPICLK polarity 0 SPICLK is held low during the INACTIVE state1 SPICLK is held high during the INACTIVE state
  [0] PHA rw — SPICLK phase 0 Data are latched on odd-numbered edges of SPICLK.1 Data are latched on even-numbered edges of SPICLK.
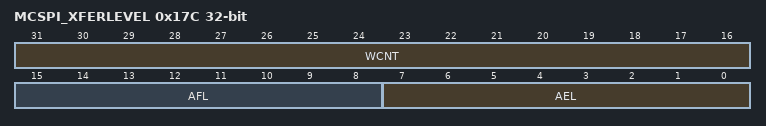
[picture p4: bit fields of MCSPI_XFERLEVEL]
0x17C MCSPI_XFERLEVEL rw — This register provides transfer levels needed while using FIFO buffer during transfer.
  [31:16] WCNT — Spi word counterThis register holds the programmable value of number of SPI word to be transferred on channel which is using the FIFO bufferWhen transfer had started, a read back in this register returns the current SPI word transfer index 0 Counter not used1 One wordFFFE 65534 MCSPI wordFFFF 65535 MCSPI word
  [15:8] AFL — Buffer Almost Full This register holds the programmable almost full level value used to determine almost full buffer condition If the user wants an interrupt or a DMA read request to be issued during a receive operation when the data buffer holds at least n bytes, then the buffer MCSPI_MODULCTRL[AFL] must be set with n-1The size of this register is defined by the generic parameter FFNBYTE 0 1 byte1 2 bytesFE 255bytesFF 256bytes
  [7:0] AEL — Buffer Almost EmptyThis register holds the programmable almost empty level value used to determine almost empty buffer condition If the user wants an interrupt or a DMA write request to be issued during a transmit operation when the data buffer is able to receive n bytes, then the buffer MCSPI_MODULCTRL[AEL] must be set with n-1 0 1 byte1 2 bytesFE 255 bytesFF 256bytes
0x180 MCSPI_DAFTX rw — This register contains the SPI words to transmit on the serial link when FIFO used and DMA address is aligned on 256 bit.This register is an image of one of MCSPI_TX(i) register corresponding to the channel which have its FIFO enabled.
  [31:0] DAFTDATA — FIFO Data to transmit with DMA 256 bit aligned address This Register is only is used when MCSPI_MODULCTRL[FDAA] is set to '1' and only one of the MCSPI_CH[i]CONF[FFEW] of enabled channels is set If these conditions are not respected any access to this register return a null value
0x1A0 MCSPI_DAFRX — This register contains the SPI words to received on the serial link when FIFO used and DMA address is aligned on 256 bit.This register is an image of one of MCSPI_RX(i) register corresponding to the channel which have its FIFO enabled.
  [31:0] DAFRDATA — FIFO Data to transmit with DMA 256 bit aligned address This Register is only is used when MCSPI_MODULCTRL[FDAA] is set to '1' and only one of the MCSPI_CH[i]CONF[FFEW] of enabled channels is set If these conditions are not respected any access to this register return a null value
